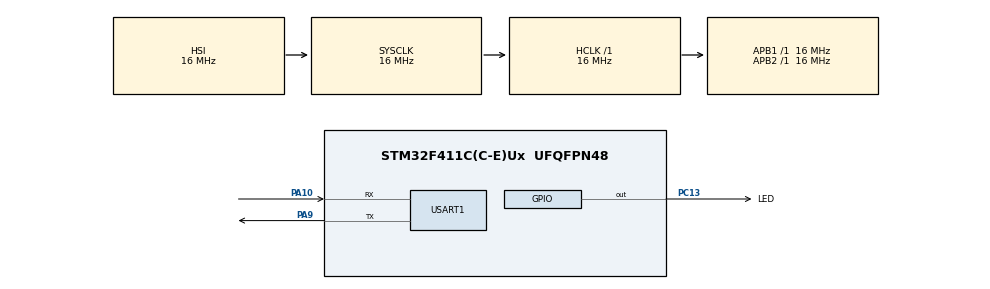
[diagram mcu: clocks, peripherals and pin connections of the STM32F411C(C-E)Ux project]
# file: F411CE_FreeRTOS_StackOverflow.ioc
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FREERTOS.Tasks01=defaultTask,24,128,StartDefaultTask,Default,NULL,Dynamic,NULL,NULL
FREERTOS.configCHECK_FOR_STACK_OVERFLOW=2
FREERTOS.configRECORD_STACK_HIGH_ADDRESS=1
FREERTOS.configUSE_NEWLIB_REENTRANT=1
Mcu.Family=STM32F4
Mcu.Name=STM32F411C(C-E)Ux
Mcu.Package=UFQFPN48
NVIC.PriorityGroup=NVIC_PRIORITYGROUP_4
NVIC.TIM1_TRG_COM_TIM11_IRQn=true\:15\:0\:false\:false\:true\:false\:false\:true
NVIC.TimeBase=TIM1_TRG_COM_TIM11_IRQn
NVIC.TimeBaseIP=TIM11
PA10.Mode=Asynchronous
PA10.Signal=USART1_RX
PA13.Mode=Trace_Asynchronous_SW
PA13.Signal=SYS_JTMS-SWDIO
PA14.Mode=Trace_Asynchronous_SW
PA14.Signal=SYS_JTCK-SWCLK
PA9.Mode=Asynchronous
PA9.Signal=USART1_TX
PB3.Mode=Trace_Asynchronous_SW
PB3.Signal=SYS_JTDO-SWO
PC13-ANTI_TAMP.GPIO_Label=LED
PC13-ANTI_TAMP.Signal=GPIO_Output
PC14-OSC32_IN.Mode=LSE-External-Oscillator
PC14-OSC32_IN.Signal=RCC_OSC32_IN
PC15-OSC32_OUT.Mode=LSE-External-Oscillator
PC15-OSC32_OUT.Signal=RCC_OSC32_OUT
PH0\ -\ OSC_IN.Mode=HSE-External-Oscillator
PH0\ -\ OSC_IN.Signal=RCC_OSC_IN
PH1\ -\ OSC_OUT.Mode=HSE-External-Oscillator
PH1\ -\ OSC_OUT.Signal=RCC_OSC_OUT
ProjectManager.HeapSize=0x200
ProjectManager.StackSize=0x400
ProjectManager.TargetToolchain=STM32CubeIDE
RCC.AHBFreq_Value=16000000
RCC.APB1Freq_Value=16000000
RCC.APB2Freq_Value=16000000
RCC.CortexFreq_Value=16000000
RCC.HSE_VALUE=25000000
RCC.HSI_VALUE=16000000
RCC.SYSCLKFreq_VALUE=16000000
RCC.VCOOutputFreq_Value=192000000
USART1.VirtualMode=VM_ASYNC
VP_FREERTOS_VS_CMSIS_V2.Mode=CMSIS_V2
VP_SYS_VS_tim11.Mode=TIM11
board=custom

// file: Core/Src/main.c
/* USER CODE BEGIN Header */
/**
  ******************************************************************************
  * @file           : main.c
  * @brief          : Main program body
  ******************************************************************************
  * @attention
  *
  * <h2><center>&copy; Copyright (c) 2021 STMicroelectronics.
  * All rights reserved.</center></h2>
  *
  * This software component is licensed by ST under BSD 3-Clause license,
  * the "License"; You may not use this file except in compliance with the
  * License. You may obtain a copy of the License at:
  *                        opensource.org/licenses/BSD-3-Clause
  *
  ******************************************************************************
  */
/* USER CODE END Header */
#include "main.h"
#include "cmsis_os.h"

/* USER CODE BEGIN Includes */
#include <stdio.h>
#include <string.h>
/* USER CODE END Includes */

UART_HandleTypeDef huart1;

/* Definitions for defaultTask */
osThreadId_t defaultTaskHandle;
const osThreadAttr_t defaultTask_attributes = {
  .name = "defaultTask",
  .stack_size = 128 * 4,
  .priority = (osPriority_t) osPriorityNormal,
};

void SystemClock_Config(void);
static void MX_GPIO_Init(void);
static void MX_USART1_UART_Init(void);
void StartDefaultTask(void *argument);

/* USER CODE BEGIN 0 */
int _write(int file, char *ptr, int len) {
    // block write to UART if it is not ready
    while(HAL_UART_GetState(&huart1) != HAL_UART_STATE_READY);

    HAL_StatusTypeDef hstatus =
        HAL_UART_Transmit(&huart1, (uint8_t*) ptr, len, HAL_MAX_DELAY);

    return (hstatus == HAL_OK ? len : 0);
}
/* USER CODE END 0 */

int main(void)
{

  /* MCU Configuration--------------------------------------------------------*/

  /* Reset of all peripherals, Initializes the Flash interface and the Systick. */
  HAL_Init();

  /* Configure the system clock */
  SystemClock_Config();

  /* Initialize all configured peripherals */
  MX_GPIO_Init();
  MX_USART1_UART_Init();

  /* Init scheduler */
  osKernelInitialize();

  /* Create the thread(s) */
  /* creation of defaultTask */
  defaultTaskHandle = osThreadNew(StartDefaultTask, NULL, &defaultTask_attributes);

  /* Start scheduler */
  osKernelStart();

  /* We should never get here as control is now taken by the scheduler */
  /* Infinite loop */
  while (1)
  {

  }
}

void SystemClock_Config(void)
{
  RCC_OscInitTypeDef RCC_OscInitStruct = {0};
  RCC_ClkInitTypeDef RCC_ClkInitStruct = {0};

  /** Configure the main internal regulator output voltage
  */
  __HAL_RCC_PWR_CLK_ENABLE();
  __HAL_PWR_VOLTAGESCALING_CONFIG(PWR_REGULATOR_VOLTAGE_SCALE1);
  /** Initializes the RCC Oscillators according to the specified parameters
  * in the RCC_OscInitTypeDef structure.
  */
  RCC_OscInitStruct.OscillatorType = RCC_OSCILLATORTYPE_HSI;
  RCC_OscInitStruct.HSIState = RCC_HSI_ON;
  RCC_OscInitStruct.HSICalibrationValue = RCC_HSICALIBRATION_DEFAULT;
  RCC_OscInitStruct.PLL.PLLState = RCC_PLL_NONE;
  if (HAL_RCC_OscConfig(&RCC_OscInitStruct) != HAL_OK)
  {
    Error_Handler();
  }
  /** Initializes the CPU, AHB and APB buses clocks
  */
  RCC_ClkInitStruct.ClockType = RCC_CLOCKTYPE_HCLK|RCC_CLOCKTYPE_SYSCLK
                              |RCC_CLOCKTYPE_PCLK1|RCC_CLOCKTYPE_PCLK2;
  RCC_ClkInitStruct.SYSCLKSource = RCC_SYSCLKSOURCE_HSI;
  RCC_ClkInitStruct.AHBCLKDivider = RCC_SYSCLK_DIV1;
  RCC_ClkInitStruct.APB1CLKDivider = RCC_HCLK_DIV1;
  RCC_ClkInitStruct.APB2CLKDivider = RCC_HCLK_DIV1;

  if (HAL_RCC_ClockConfig(&RCC_ClkInitStruct, FLASH_LATENCY_0) != HAL_OK)
  {
    Error_Handler();
  }
}

static void MX_USART1_UART_Init(void)
{

  huart1.Instance = USART1;
  huart1.Init.BaudRate = 115200;
  huart1.Init.WordLength = UART_WORDLENGTH_8B;
  huart1.Init.StopBits = UART_STOPBITS_1;
  huart1.Init.Parity = UART_PARITY_NONE;
  huart1.Init.Mode = UART_MODE_TX_RX;
  huart1.Init.HwFlowCtl = UART_HWCONTROL_NONE;
  huart1.Init.OverSampling = UART_OVERSAMPLING_16;
  if (HAL_UART_Init(&huart1) != HAL_OK)
  {
    Error_Handler();
  }

}

static void MX_GPIO_Init(void)
{
  GPIO_InitTypeDef GPIO_InitStruct = {0};

  /* GPIO Ports Clock Enable */
  __HAL_RCC_GPIOC_CLK_ENABLE();
  __HAL_RCC_GPIOH_CLK_ENABLE();
  __HAL_RCC_GPIOA_CLK_ENABLE();
  __HAL_RCC_GPIOB_CLK_ENABLE();

  /*Configure GPIO pin Output Level */
  HAL_GPIO_WritePin(LED_GPIO_Port, LED_Pin, GPIO_PIN_RESET);

  /*Configure GPIO pin : LED_Pin */
  GPIO_InitStruct.Pin = LED_Pin;
  GPIO_InitStruct.Mode = GPIO_MODE_OUTPUT_PP;
  GPIO_InitStruct.Pull = GPIO_NOPULL;
  GPIO_InitStruct.Speed = GPIO_SPEED_FREQ_LOW;
  HAL_GPIO_Init(LED_GPIO_Port, &GPIO_InitStruct);

}

void StartDefaultTask(void *argument)
{
  /* USER CODE BEGIN 5 */
  uint32_t counter = 0xbeefbeef;
  /* Infinite loop */
  for(;;)
  {
    HAL_GPIO_TogglePin(LED_GPIO_Port, LED_Pin);
    printf("Counting, %lu %lu %lu %lu. No problem?\r\n", counter++, counter++, counter++, counter++);
    osDelay(500);
  }
  /* USER CODE END 5 */
}

void HAL_TIM_PeriodElapsedCallback(TIM_HandleTypeDef *htim)
{
  if (htim->Instance == TIM11) {
    HAL_IncTick();
  }
}

void Error_Handler(void)
{
  __disable_irq();
  while (1)
  {
  }
}

/************************ (C) COPYRIGHT STMicroelectronics *****END OF FILE****/

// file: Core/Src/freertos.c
/* USER CODE BEGIN Header */
/**
  ******************************************************************************
  * File Name          : freertos.c
  * Description        : Code for freertos applications
  ******************************************************************************
  * @attention
  *
  * <h2><center>&copy; Copyright (c) 2021 STMicroelectronics.
  * All rights reserved.</center></h2>
  *
  * This software component is licensed by ST under Ultimate Liberty license
  * SLA0044, the "License"; You may not use this file except in compliance with
  * the License. You may obtain a copy of the License at:
  *                             www.st.com/SLA0044
  *
  ******************************************************************************
  */
/* USER CODE END Header */

#include "FreeRTOS.h"
#include "task.h"
#include "main.h"

/* Hook prototypes */
void vApplicationStackOverflowHook(xTaskHandle xTask, signed char *pcTaskName);

/* USER CODE BEGIN 4 */
void vApplicationStackOverflowHook(xTaskHandle xTask, signed char *pcTaskName)
{
   /* Run time stack overflow checking is performed if
   configCHECK_FOR_STACK_OVERFLOW is defined to 1 or 2. This hook function is
   called if a stack overflow is detected. */
#ifdef CATCH_STACK_OVERFLOW
#ifdef DEBUG
  __BKPT();
#else
  for(;;) {
    HAL_GPIO_TogglePin(LED_GPIO_Port, LED_Pin);
    HAL_Delay(100);
  }
#endif
#endif
}
/* USER CODE END 4 */

/************************ (C) COPYRIGHT STMicroelectronics *****END OF FILE****/
